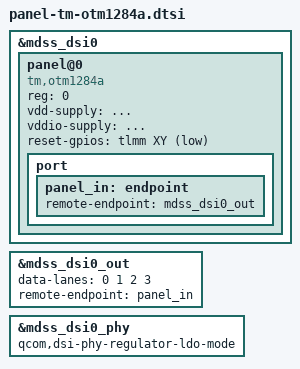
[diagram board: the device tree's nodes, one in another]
&mdss_dsi0 {
	panel@0 {
		compatible = "tm,otm1284a";
		reg = <0>;

		vdd-supply = <&...>;
		vddio-supply = <&...>;
		reset-gpios = <&tlmm XY GPIO_ACTIVE_LOW>;

		port {
			panel_in: endpoint {
				remote-endpoint = <&mdss_dsi0_out>;
			};
		};
	};
};

&mdss_dsi0_out {
	data-lanes = <0 1 2 3>;
	remote-endpoint = <&panel_in>;
};

&mdss_dsi0_phy {
	qcom,dsi-phy-regulator-ldo-mode;
};
